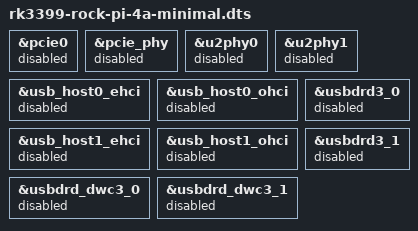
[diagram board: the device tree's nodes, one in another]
#include "rk3399-rock-pi-4a.dts"

&pcie0 {
	status = "disabled";
};

&pcie_phy {
	status = "disabled";
};

&u2phy0 {
	status = "disabled";
};

&u2phy1 {
	status = "disabled";
};

&usb_host0_ehci {
	status = "disabled";
};

&usb_host0_ohci {
	status = "disabled";
};

&usb_host1_ehci {
	status = "disabled";
};

&usb_host1_ohci {
	status = "disabled";
};

&usbdrd3_0 {
	status = "disabled";
};

&usbdrd3_1 {
	status = "disabled";
};

&usbdrd_dwc3_0 {
	status = "disabled";
};

&usbdrd_dwc3_1 {
	status = "disabled";
};

